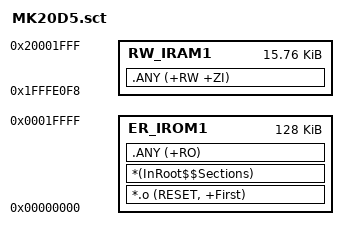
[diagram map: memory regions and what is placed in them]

LR_IROM1 0x00000000 0x20000  {    ; load region size_region (132k)
  ER_IROM1 0x00000000 0x20000  {  ; load address = execution address
   *.o (RESET, +First)
   *(InRoot$$Sections)
   .ANY (+RO)
  }
  ; 8_byte_aligned(62 vect * 4 bytes) =  8_byte_aligned(0xF8) = 0xF8
  ; 0x4000 - 0xF8 = 0x3F08
  RW_IRAM1 0x1FFFE0F8 0x3F08 {
   .ANY (+RW +ZI)
  }
}

